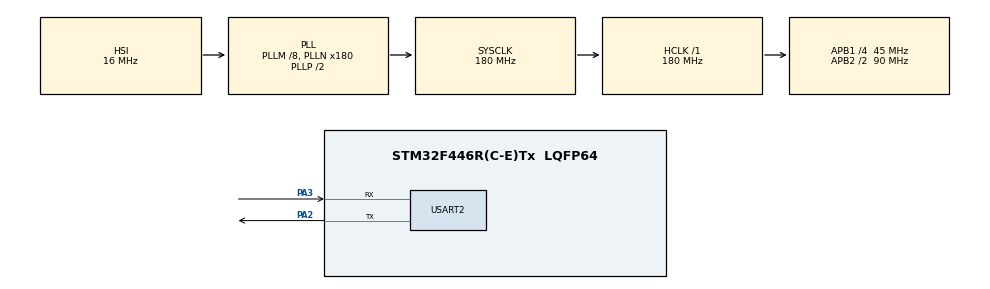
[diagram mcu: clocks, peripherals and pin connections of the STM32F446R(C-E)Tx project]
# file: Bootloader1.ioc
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Mcu.Family=STM32F4
RCC.CortexFreq_Value=180000000
RCC.APB1CLKDivider=RCC_HCLK_DIV4
RCC.SYSCLKSource=RCC_SYSCLKSOURCE_PLLCLK
ProjectManager.StackSize=0x400
PA13.Signal=SYS_JTMS-SWDIO
PA3.Mode=Asynchronous
ProjectManager.TargetToolchain=STM32CubeIDE
RCC.HCLKFreq_Value=180000000
RCC.APB2TimFreq_Value=180000000
RCC.USBFreq_Value=180000000
RCC.AHBFreq_Value=180000000
board=custom
RCC.VCOOutputFreq_Value=360000000
RCC.APB2Freq_Value=90000000
PA14.Mode=Serial_Wire
PA13.Mode=Serial_Wire
Mcu.Name=STM32F446R(C-E)Tx
PA2.Signal=USART2_TX
RCC.SYSCLKFreq_VALUE=180000000
Mcu.Package=LQFP64
USART2.VirtualMode=VM_ASYNC
PA14.Signal=SYS_JTCK-SWCLK
ProjectManager.HeapSize=0x200
NVIC.PriorityGroup=NVIC_PRIORITYGROUP_4
RCC.APB2CLKDivider=RCC_HCLK_DIV2
RCC.PLLM=8
RCC.PLLN=180
RCC.APB1TimFreq_Value=90000000
PA2.Mode=Asynchronous
RCC.APB1Freq_Value=45000000
PA3.Signal=USART2_RX

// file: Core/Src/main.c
/* USER CODE BEGIN Header */
/**
  ******************************************************************************
  * @file           : main.c
  * @brief          : Main program body
  ******************************************************************************
  * @attention
  *
  * <h2><center>&copy; Copyright (c) 2026 STMicroelectronics.
  * All rights reserved.</center></h2>
  *
  * This software component is licensed by ST under BSD 3-Clause license,
  * the "License"; You may not use this file except in compliance with the
  * License. You may obtain a copy of the License at:
  *                        opensource.org/licenses/BSD-3-Clause
  *
  ******************************************************************************
  */
/* USER CODE END Header */
#include "main.h"

/* USER CODE BEGIN Includes */
#include "bl_jump.h"
#include <string.h>
#include"OTA.h"
#include"ota_image.h"
/* USER CODE END Includes */

UART_HandleTypeDef huart2;

void SystemClock_Config(void);
static void MX_GPIO_Init(void);
static void MX_USART2_UART_Init(void);

/* USER CODE BEGIN 0 */
static uint32_t mem_base = 0;  // used with external or dual flash
static uint32_t mem_cursor = 0;
static uint32_t ota_image_total_size = 16;  // expected OTA Header size

void ota_mem_set_total_size(uint32_t size)
{
    ota_image_total_size = size;
}

int ota_read_mem(uint8_t *buf, uint32_t len)
{
    if (mem_cursor + len > ota_image_total_size)
        return -1;

    memcpy(buf, &ota_image_bin[mem_base + mem_cursor], len);  // this function should be replaced accordingly

    mem_cursor += len;
    return 0;
}

/* USER CODE END 0 */
int main(void)
{

  /* MCU Configuration--------------------------------------------------------*/

  /* Reset of all peripherals, Initializes the Flash interface and the Systick. */
  HAL_Init();

  /* Configure the system clock */
  SystemClock_Config();

  /* Initialize all configured peripherals */
  MX_GPIO_Init();
  MX_USART2_UART_Init();
  /* USER CODE BEGIN 2 */

  HAL_Delay(100);
  HAL_UART_Transmit(&huart2,  (uint8_t*)"inside bootloader!!\r\n", 21, 100);

  if(check_ota_request()==1){
	  HAL_UART_Transmit(&huart2,(uint8_t*)"OTA is requesting!!\r\n", 21, 100);
	  HAL_Delay(100);

	  ota_stream_t stream =
	  	  {
	  	      .read = ota_read_mem,
	  	      .set_total_size = ota_mem_set_total_size
	  	  };
	  bl_ota_ctx_t ctx;
	  if (bl_ota_run(&ctx, &stream) != 0)
	  	 {
	  		 HAL_UART_Transmit(&huart2, (uint8_t *)"OTA Failed...\n", 14, 100);
	  }
	  else {
		     HAL_UART_Transmit(&huart2, (uint8_t *)"OTA Flashed Successfully, Jumping to app...\n", 44, 100);
	  }
  }
  int err=bootloader_is_app_valid();
  if(err != 0){
	  HAL_UART_Transmit(&huart2, "Failed to jump!!\r\n", 18, 100);
	  if(err==1)
		  HAL_UART_Transmit(&huart2, "magic number!!\r\n", 18, 100);
	  if(err==2)
	  	  HAL_UART_Transmit(&huart2, "reset handler!!\r\n", 18, 100);
	  if(err==3)
	  	  HAL_UART_Transmit(&huart2, "size!!\r\n", 18, 100);
	  if(err==4)
	  	  HAL_UART_Transmit(&huart2, "CRC32!!\r\n", 18, 100);

  }
  else {
	  JumpToApplication();
  }

  /* USER CODE END 2 */

  /* Infinite loop */
  while (1)
  {

    /* USER CODE BEGIN 3 */
	  HAL_UART_Transmit(&huart2, (uint8_t *)"still inside bootloader!!\r\n", 27, 100);
	  HAL_Delay(100);
  }
  /* USER CODE END 3 */
}

void SystemClock_Config(void)
{
  RCC_OscInitTypeDef RCC_OscInitStruct = {0};
  RCC_ClkInitTypeDef RCC_ClkInitStruct = {0};

  /** Configure the main internal regulator output voltage
  */
  __HAL_RCC_PWR_CLK_ENABLE();
  __HAL_PWR_VOLTAGESCALING_CONFIG(PWR_REGULATOR_VOLTAGE_SCALE1);
  /** Initializes the RCC Oscillators according to the specified parameters
  * in the RCC_OscInitTypeDef structure.
  */
  RCC_OscInitStruct.OscillatorType = RCC_OSCILLATORTYPE_HSI;
  RCC_OscInitStruct.HSIState = RCC_HSI_ON;
  RCC_OscInitStruct.HSICalibrationValue = RCC_HSICALIBRATION_DEFAULT;
  RCC_OscInitStruct.PLL.PLLState = RCC_PLL_ON;
  RCC_OscInitStruct.PLL.PLLSource = RCC_PLLSOURCE_HSI;
  RCC_OscInitStruct.PLL.PLLM = 8;
  RCC_OscInitStruct.PLL.PLLN = 180;
  RCC_OscInitStruct.PLL.PLLP = RCC_PLLP_DIV2;
  RCC_OscInitStruct.PLL.PLLQ = 2;
  RCC_OscInitStruct.PLL.PLLR = 2;
  if (HAL_RCC_OscConfig(&RCC_OscInitStruct) != HAL_OK)
  {
    Error_Handler();
  }
  /** Activate the Over-Drive mode
  */
  if (HAL_PWREx_EnableOverDrive() != HAL_OK)
  {
    Error_Handler();
  }
  /** Initializes the CPU, AHB and APB buses clocks
  */
  RCC_ClkInitStruct.ClockType = RCC_CLOCKTYPE_HCLK|RCC_CLOCKTYPE_SYSCLK
                              |RCC_CLOCKTYPE_PCLK1|RCC_CLOCKTYPE_PCLK2;
  RCC_ClkInitStruct.SYSCLKSource = RCC_SYSCLKSOURCE_PLLCLK;
  RCC_ClkInitStruct.AHBCLKDivider = RCC_SYSCLK_DIV1;
  RCC_ClkInitStruct.APB1CLKDivider = RCC_HCLK_DIV4;
  RCC_ClkInitStruct.APB2CLKDivider = RCC_HCLK_DIV2;

  if (HAL_RCC_ClockConfig(&RCC_ClkInitStruct, FLASH_LATENCY_5) != HAL_OK)
  {
    Error_Handler();
  }
}

static void MX_USART2_UART_Init(void)
{

  huart2.Instance = USART2;
  huart2.Init.BaudRate = 115200;
  huart2.Init.WordLength = UART_WORDLENGTH_8B;
  huart2.Init.StopBits = UART_STOPBITS_1;
  huart2.Init.Parity = UART_PARITY_NONE;
  huart2.Init.Mode = UART_MODE_TX_RX;
  huart2.Init.HwFlowCtl = UART_HWCONTROL_NONE;
  huart2.Init.OverSampling = UART_OVERSAMPLING_16;
  if (HAL_UART_Init(&huart2) != HAL_OK)
  {
    Error_Handler();
  }

}

static void MX_GPIO_Init(void)
{

  /* GPIO Ports Clock Enable */
  __HAL_RCC_GPIOA_CLK_ENABLE();

}

void Error_Handler(void)
{
  __disable_irq();
  while (1)
  {
  }
}

/************************ (C) COPYRIGHT STMicroelectronics *****END OF FILE****/
